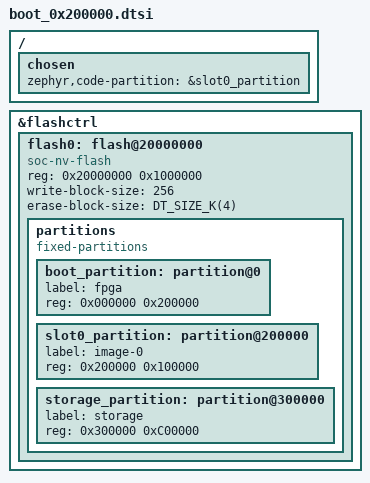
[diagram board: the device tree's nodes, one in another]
/*
 * Copyright (c) 2025 tinyVision.ai Inc.
 *
 * SPDX-License-Identifier: Apache-2.0
 */

#include <mem.h>

/ {
	chosen {
		zephyr,code-partition = &slot0_partition;
	};
};

&flashctrl {
	flash0: flash@20000000 {
		#address-cells = <1>;
		#size-cells = <0>;
		compatible = "soc-nv-flash";
		reg = <0x20000000 0x1000000>;
		write-block-size = <256>;
		erase-block-size = <DT_SIZE_K(4)>;
		//jedec-id = [ef 60 18];
		partitions {
			compatible = "fixed-partitions";
			#address-cells = <1>;
			#size-cells = <1>;

			boot_partition: partition@0 {
				label = "fpga";
				reg = <0x000000 0x200000>;
			};

			slot0_partition: partition@200000 {
				label = "image-0";
				reg = <0x200000 0x100000>;
			};

			storage_partition: partition@300000 {
				label = "storage";
				reg = <0x300000 0xC00000>;
			};
		};
	};
};
